VERSION ""

NS_ :

BS_:

BU_: USS RZCU RBCU MCU
VAL_TABLE_ vtbSensorReqCause 15 "SNA" 2 "by Request 2" 1 "by Request 1" 0 "normal cycle" ;
VAL_TABLE_ vtbErrorDescription 255 "ERROR" ;

BO_ 3221225472 VECTOR__INDEPENDENT_SIG_MSG: 0 Vector__XXX
 SG_ RightRear_RPM : 0|16@1- (1,0) [-32768|32767] "" Vector__XXX
 SG_ LeftRear_RPM : 0|16@1- (1,0) [-32768|32767] "" Vector__XXX
 SG_ LeftRear_MotorRPM : 0|16@1- (1,0) [-32768|32767] "" Vector__XXX
 SG_ LeftRear_MotorDirection : 0|1@1+ (1,0) [0|1] "" Vector__XXX
 SG_ RightRear_MotorRPM : 0|16@1- (1,0) [-32768|32767] "" Vector__XXX
 SG_ RightRear_MotorDirection : 0|1@1+ (1,0) [0|1] "" Vector__XXX

BO_ 81 RZCU_EmergencyOnOff_CTL_MSG: 1 RZCU
 SG_ Emergency_Light : 0|1@1+ (1,0) [0|0] ""  RBCU

BO_ 68 RZCU_VehicleStart_CTL_MSG: 1 RZCU
 SG_ Ignition_Status : 0|2@1+ (1,0) [0|3] ""  MCU

BO_ 608 MCU_OTAResult_STATUS_MSG: 1 MCU
 SG_ MCU_OTAResult : 0|1@1+ (1,0) [0|1] ""  RZCU

BO_ 352 USS_OTAResult_STATUS_MSG: 1 USS
 SG_ USS_OTAResult : 0|1@1+ (1,0) [0|1] ""  RZCU

BO_ 864 RBCU_OTAResult_STATUS_MSG: 1 RBCU
 SG_ RBCU_OTAResult : 0|1@1+ (1,0) [0|1] ""  RZCU

BO_ 628 MCU_Alive_INFO_20MSG: 1 MCU
 SG_ MCU_Alive : 0|1@1+ (1,0) [0|1] ""  RZCU

BO_ 376 USS_Alive_INFO_20MSG: 1 USS
 SG_ USS_Alive : 0|1@1+ (1,0) [0|1] ""  RZCU

BO_ 884 RBCU_Alive_INFO_20MSG: 1 RBCU
 SG_ RBCU_Alive : 0|1@1+ (1,0) [0|1] ""  RZCU

BO_ 274 USS_UltraSoundVal_INFO_50MSG: 2 USS
 SG_ RightRear_UltraSoundVal : 8|8@1+ (1,0) [0|255] ""  RZCU
 SG_ LeftRear_UltraSoundVal : 0|8@1+ (1,0) [0|255] ""  RZCU

BO_ 17 RZCU_Wheel_CTL_MSG: 3 RZCU
 SG_ Transition_Status : 16|3@1+ (1,0) [0|0] "" Vector__XXX
 SG_ RPM_CTL : 0|16@1- (1,0) [0|0] ""  MCU

BO_ 33 RZCU_WakeUp_CTL_MSG: 1 RZCU
 SG_ RearZone_WakeUp : 0|1@1+ (1,0) [0|1] ""  MCU,RBCU,RZCU,USS

BO_ 49 RZCU_TurnLight_CTL_MSG: 1 RZCU
 SG_ RightRear_Light : 1|1@1+ (1,0) [0|1] ""  RBCU
 SG_ LeftRear_Light : 0|1@1+ (1,0) [0|1] ""  RBCU

BO_ 32 RZCU_OTA_USS_MSG: 8 RZCU
 SG_ USS_OTA : 0|64@1+ (1,0) [0|1.84467440737096E+19] ""  USS

BO_ 16 RZCU_OTA_RBCU_MSG: 8 RZCU
 SG_ RBCU_OTA : 0|64@1+ (1,0) [0|1.84467440737096E+19] ""  RBCU

BO_ 48 RZCU_OTA_MCU_MSG: 8 RZCU
 SG_ MCU_OTA : 0|64@1+ (1,0) [0|1.84467440737096E+19] ""  MCU

BO_ 97 RZCU_ObsDetectDist_CTL_MSG: 1 RZCU
 SG_ ObstacleDetection_Distance : 0|8@1+ (1,0) [0|255] ""  USS

BO_ 65 RZCU_BrakeLight_CTL_MSG: 1 RZCU
 SG_ Rear_BrakeLight : 0|1@1+ (1,0) [0|1] ""  RBCU

BO_ 516 MCU_RearMotor_STATUS_10MSG: 4 MCU
 SG_ VCU_RPM : 16|16@1- (1,0) [0|0] "" Vector__XXX
 SG_ MCU_Velocity : 0|16@1- (1,0) [0|0] ""  RZCU

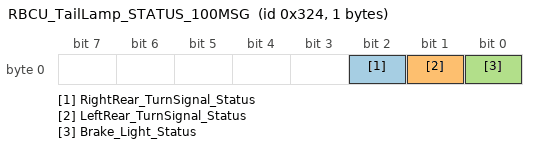
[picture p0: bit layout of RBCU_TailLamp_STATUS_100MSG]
BO_ 804 RBCU_TailLamp_STATUS_100MSG: 1 RBCU
 SG_ RightRear_TurnSignal_Status : 2|1@1+ (1,0) [0|1] ""  RZCU
 SG_ LeftRear_TurnSignal_Status : 1|1@1+ (1,0) [0|1] ""  RZCU
 SG_ Brake_Light_Status : 0|1@1+ (1,0) [0|1] ""  RZCU

CM_ BO_ 3221225472 "This is a message for not used signals, created by Vector CANdb++ DBC OLE DB Provider.";
BA_DEF_  "DatabaseVersion" STRING ;
BA_DEF_  "Manufacturer" STRING ;
BA_DEF_ BU_  "NodeLayerModules" STRING ;
BA_DEF_  "BusType" STRING ;
BA_DEF_ SG_  "GenSigSendType" ENUM  "Cyclic","OnWrite","OnWriteWithRepetition","OnChange","OnChangeWithRepetition","IfActive","IfActiveWithRepetition","NoSigSendType","NotUsed","NotUsed","NotUsed","NotUsed","NotUsed";
BA_DEF_ BO_  "GenMsgSendType" ENUM  "Cyclic","NotUsed","NotUsed","NotUsed","NotUsed","Cyclic","NotUsed","IfActive","NoMsgSendType","NotUsed","vector_leerstring";
BA_DEF_ BO_  "GenMsgCycleTime" INT 0 50000;
BA_DEF_ BO_  "GenMsgCycleTimeFast" INT 0 50000;
BA_DEF_ BO_  "GenMsgILSupport" ENUM  "No","Yes";
BA_DEF_DEF_  "DatabaseVersion" "";
BA_DEF_DEF_  "Manufacturer" "Vector";
BA_DEF_DEF_  "NodeLayerModules" "CANoeILNLVector.dll";
BA_DEF_DEF_  "BusType" "CAN";
BA_DEF_DEF_  "GenSigSendType" "Cyclic";
BA_DEF_DEF_  "GenMsgSendType" "NoMsgSendType";
BA_DEF_DEF_  "GenMsgCycleTime" 200;
BA_DEF_DEF_  "GenMsgCycleTimeFast" 20;
BA_DEF_DEF_  "GenMsgILSupport" "Yes";
BA_ "DatabaseVersion" "1.1";
BA_ "GenMsgCycleTime" BO_ 628 20;
BA_ "GenMsgCycleTime" BO_ 376 20;
BA_ "GenMsgCycleTime" BO_ 884 20;
BA_ "GenMsgCycleTimeFast" BO_ 274 50;
BA_ "GenMsgCycleTime" BO_ 274 50;
BA_ "GenMsgCycleTime" BO_ 516 10;
BA_ "GenMsgCycleTime" BO_ 804 100;
BA_ "GenMsgCycleTimeFast" BO_ 804 100;
BA_ "GenSigSendType" SG_ 3221225472 RightRear_RPM 7;
BA_ "GenSigSendType" SG_ 81 Emergency_Light 7;
BA_ "GenSigSendType" SG_ 68 Ignition_Status 7;
BA_ "GenSigSendType" SG_ 608 MCU_OTAResult 7;
BA_ "GenSigSendType" SG_ 352 USS_OTAResult 7;
BA_ "GenSigSendType" SG_ 864 RBCU_OTAResult 7;
BA_ "GenSigSendType" SG_ 628 MCU_Alive 5;
BA_ "GenSigSendType" SG_ 376 USS_Alive 5;
BA_ "GenSigSendType" SG_ 884 RBCU_Alive 5;
BA_ "GenSigSendType" SG_ 274 RightRear_UltraSoundVal 7;
BA_ "GenSigSendType" SG_ 274 LeftRear_UltraSoundVal 7;
BA_ "GenSigSendType" SG_ 17 Transition_Status 7;
BA_ "GenSigSendType" SG_ 17 RPM_CTL 7;
BA_ "GenSigSendType" SG_ 33 RearZone_WakeUp 7;
BA_ "GenSigSendType" SG_ 49 RightRear_Light 7;
BA_ "GenSigSendType" SG_ 49 LeftRear_Light 7;
BA_ "GenSigSendType" SG_ 32 USS_OTA 7;
BA_ "GenSigSendType" SG_ 16 RBCU_OTA 7;
BA_ "GenSigSendType" SG_ 48 MCU_OTA 7;
BA_ "GenSigSendType" SG_ 97 ObstacleDetection_Distance 7;
BA_ "GenSigSendType" SG_ 65 Rear_BrakeLight 7;
BA_ "GenSigSendType" SG_ 516 VCU_RPM 7;
BA_ "GenSigSendType" SG_ 516 MCU_Velocity 7;
BA_ "GenSigSendType" SG_ 804 RightRear_TurnSignal_Status 7;
BA_ "GenSigSendType" SG_ 804 LeftRear_TurnSignal_Status 7;
BA_ "GenSigSendType" SG_ 804 Brake_Light_Status 7;
